VERSION ""

NS_ :

BS_:

BU_: XXX

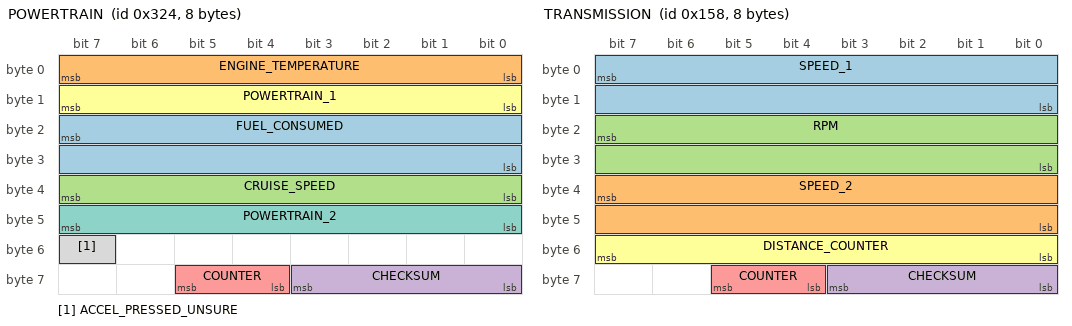
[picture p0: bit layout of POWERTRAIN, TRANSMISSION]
BO_ 804 POWERTRAIN: 8 XXX
 SG_ FUEL_CONSUMED : 23|16@0+ (1,0) [0|65535] "" XXX
 SG_ ENGINE_TEMPERATURE : 7|8@0+ (1,0) [0|255] "Degrees Celsius" XXX
 SG_ CRUISE_SPEED : 39|8@0+ (1,0) [0|255] "km/h" XXX
 SG_ CHECKSUM : 56|4@1+ (1,0) [0|15] "" XXX
 SG_ COUNTER : 61|2@0+ (1,0) [0|3] "" XXX
 SG_ POWERTRAIN_1 : 8|8@1+ (1,0) [0|255] "" XXX
 SG_ POWERTRAIN_2 : 47|8@0- (1,0) [0|255] "" XXX
 SG_ ACCEL_PRESSED_UNSURE : 55|1@0+ (1,0) [0|255] "" XXX

BO_ 660 LIGHTS: 8 XXX
 SG_ LEFT_TURN_SIGNAL : 5|1@0+ (1,0) [0|1] "" XXX
 SG_ RIGHT_TURN_SIGNAL : 6|1@0+ (1,0) [0|1] "" XXX

BO_ 344 TRANSMISSION: 8 XXX
 SG_ SPEED_1 : 7|16@0+ (0.01,0) [0|65535] "km/h" XXX
 SG_ SPEED_2 : 39|16@0+ (0.01,0) [0|65535] "km/h" XXX
 SG_ RPM : 23|16@0+ (1,0) [0|65535] "" XXX
 SG_ CHECKSUM : 56|4@1+ (1,0) [0|15] "" XXX
 SG_ COUNTER : 61|2@0+ (1,0) [0|3] "" XXX
 SG_ DISTANCE_COUNTER : 55|8@0+ (1,0) [0|255] "" XXX

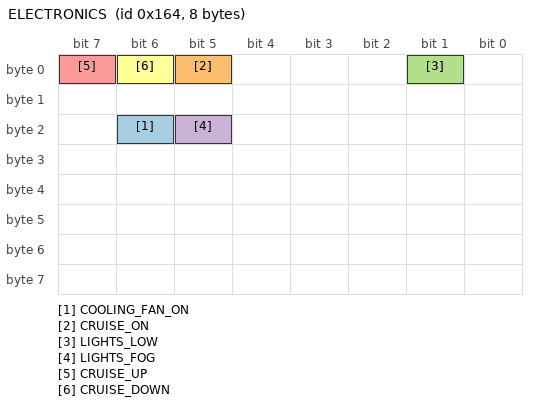
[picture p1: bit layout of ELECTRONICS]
BO_ 356 ELECTRONICS: 8 XXX
 SG_ COOLING_FAN_ON : 22|1@0+ (1,0) [0|1] "" XXX
 SG_ CRUISE_ON : 5|1@0+ (1,0) [0|1] "" XXX
 SG_ LIGHTS_LOW : 1|1@0+ (1,0) [0|1] "" XXX
 SG_ LIGHTS_FOG : 21|1@0+ (1,0) [0|1] "" XXX
 SG_ CRUISE_UP : 7|1@0+ (1,0) [0|1] "" XXX
 SG_ CRUISE_DOWN : 6|1@0+ (1,0) [0|1] "" XXX

CM_ SG_ 356 COOLING_FAN_ON "Might be A/C";
